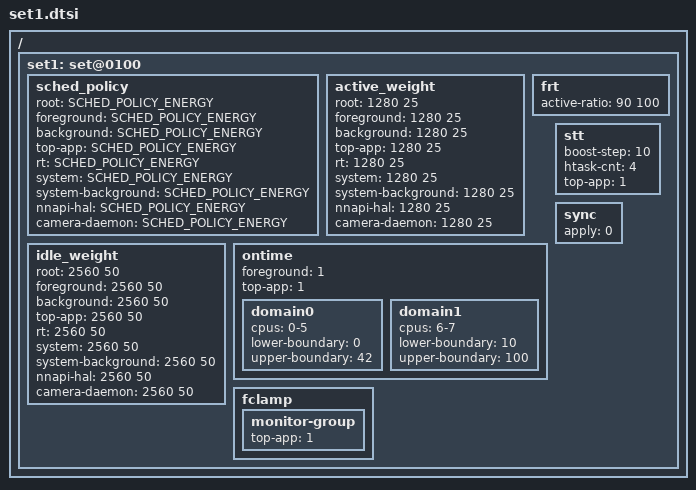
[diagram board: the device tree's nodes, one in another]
/ {
	/* power-scenario mode - default */
	set1: set@0100 {
		/* schedudling policy */
		sched_policy {
			root			= <SCHED_POLICY_ENERGY>;
			foreground 		= <SCHED_POLICY_ENERGY>;
			background		= <SCHED_POLICY_ENERGY>;
			top-app			= <SCHED_POLICY_ENERGY>;
			rt			= <SCHED_POLICY_ENERGY>;
			system			= <SCHED_POLICY_ENERGY>;
			system-background	= <SCHED_POLICY_ENERGY>;
			nnapi-hal		= <SCHED_POLICY_ENERGY>;
			camera-daemon		= <SCHED_POLICY_ENERGY>;
		};

		/* weight (%) applied to active cpu's efficiency */
		active_weight {	   		/*  LIT BIG */
			root            	= <1280  25>;
			foreground      	= <1280  25>;
			background      	= <1280  25>;
			top-app         	= <1280  25>;
			rt			= <1280  25>;
			system			= <1280  25>;
			system-background	= <1280  25>;
			nnapi-hal		= <1280  25>;
			camera-daemon		= <1280  25>;
		};

		/* weight (%) applied to idle cpu's efficiency */
		idle_weight {	   		/*  LIT BIG */
			root            	= <2560  50>;
			foreground      	= <2560  50>;
			background      	= <2560  50>;
			top-app         	= <2560  50>;
			rt			= <2560  50>;
			system			= <2560  50>;
			system-background	= <2560  50>;
			nnapi-hal		= <2560  50>;
			camera-daemon		= <2560  50>;
		};

		frt {	   			/* LIT BIG */
			active-ratio		= < 90 100>;
		};

		/* Ontime Migration */
		ontime {
			foreground 	= <1>;
			top-app		= <1>;

			domain0 {
				cpus = "0-5";
				lower-boundary = <0>;
				upper-boundary = <42>;
			};
			domain1 {
				cpus = "6-7";
				lower-boundary = <10>;
				upper-boundary = <100>;
			};
		};

		stt {
			boost-step		= <10>;
			htask-cnt		= <4>;
			top-app			= <1>;
		};

		fclamp {
			monitor-group {
				top-app         = <1>;
			};
		};

		sync {
			apply = <0>;
		};
	};
};
